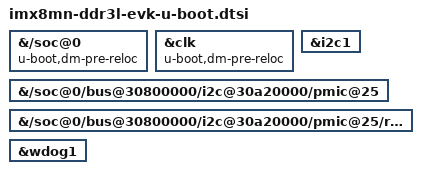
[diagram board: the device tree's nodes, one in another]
// SPDX-License-Identifier: GPL-2.0+
/*
 * Copyright 2019 NXP
 */

#include "imx8mn-u-boot.dtsi"


&{/soc@0} {
	u-boot,dm-pre-reloc;
	u-boot,dm-spl;
};

&clk {
	u-boot,dm-spl;
	u-boot,dm-pre-reloc;
	/delete-property/ assigned-clocks;
	/delete-property/ assigned-clock-parents;
	/delete-property/ assigned-clock-rates;
};

&i2c1 {
	u-boot,dm-spl;
};

&{/soc@0/bus@30800000/i2c@30a20000/pmic@25} {
	u-boot,dm-spl;
};

&{/soc@0/bus@30800000/i2c@30a20000/pmic@25/regulators} {
	u-boot,dm-spl;
};

&wdog1 {
	u-boot,dm-spl;
};
